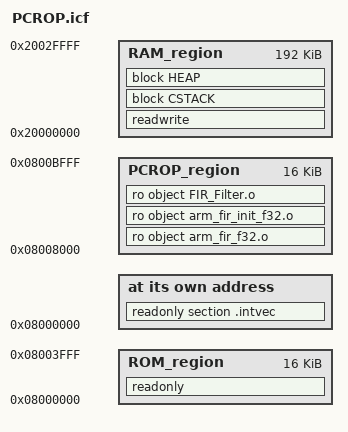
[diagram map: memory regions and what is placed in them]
/*###ICF### Section handled by ICF editor, don't touch! ****/
/*-Editor annotation file-*/
/* IcfEditorFile="$TOOLKIT_DIR$\config\ide\IcfEditor\cortex_v1_0.xml" */
/*-Specials-*/
define symbol __ICFEDIT_intvec_start__ = 0x08000000;
/*-Memory Regions-*/
define symbol __ICFEDIT_region_ROM_start__    = 0x08000000;
define symbol __ICFEDIT_region_ROM_end__      = 0x08003FFF;

define symbol __ICFEDIT_region_PCROP_start__    = 0x08008000;
define symbol __ICFEDIT_region_PCROP_end__      = 0x0800BFFF;

define symbol __ICFEDIT_region_RAM_start__    = 0x20000000;
define symbol __ICFEDIT_region_RAM_end__      = 0x2002FFFF;

/*-Sizes-*/
define symbol __ICFEDIT_size_cstack__ = 0x400;
define symbol __ICFEDIT_size_heap__   = 0x200;
/**** End of ICF editor section. ###ICF###*/


define memory mem with size = 4G;
define region ROM_region     = mem:[from __ICFEDIT_region_ROM_start__   to __ICFEDIT_region_ROM_end__];
define region RAM_region     = mem:[from __ICFEDIT_region_RAM_start__   to __ICFEDIT_region_RAM_end__];
define region PCROP_region   = mem:[from __ICFEDIT_region_PCROP_start__   to __ICFEDIT_region_PCROP_end__];

define block CSTACK    with alignment = 8, size = __ICFEDIT_size_cstack__   { };
define block HEAP      with alignment = 8, size = __ICFEDIT_size_heap__     { };

initialize by copy { readwrite };
do not initialize  { section .noinit };

place at address mem:__ICFEDIT_intvec_start__ { readonly section .intvec };

place in ROM_region   { readonly };
/* Place IP Code in sector 2 which will be PCROP-ed */
place in PCROP_region   { ro object arm_fir_f32.o,
                          ro object arm_fir_init_f32.o,
                          ro object FIR_Filter.o}; 
 
place in RAM_region   { readwrite, block CSTACK, block HEAP };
